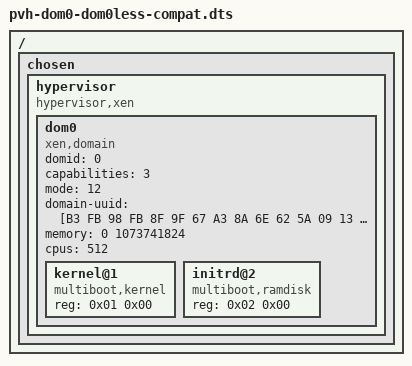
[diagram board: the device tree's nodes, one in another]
/dts-v1/;

/ {
	chosen {
		hypervisor {
			compatible = "hypervisor,xen", "xen,x86";

			dom0 {
				#address-cells = <1>;
				#size-cells = <1>;

				compatible = "xen,domain";

				domid = <0>;

				capabilities = <3>;
				mode = <12>;

				domain-uuid = [B3 FB 98 FB 8F 9F 67 A3 8A 6E 62 5A 09 13 F0 8C];

				memory = <0 1073741824>;
				cpus = <512>;

				kernel@1 {
					compatible = "multiboot,kernel", "multiboot,module";
					reg = <0x01 0x00>;
				};

				initrd@2 {
					compatible = "multiboot,ramdisk", "multiboot,module";
					reg = <0x02 0x00>;
				};
			};

		};
	};
};
